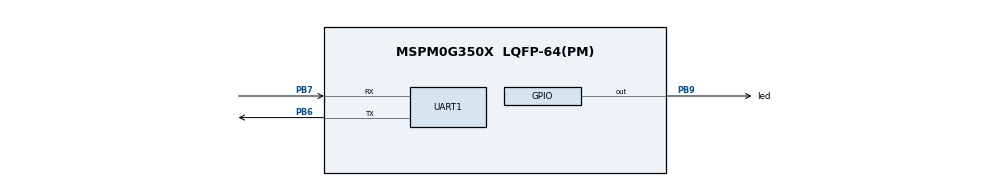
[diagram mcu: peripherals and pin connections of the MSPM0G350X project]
/**
 *
 * @cliArgs --device "MSPM0G350X" --part "Default" --package "LQFP-64(PM)" --product "mspm0_sdk@2.10.00.04"
 * @versions {"tool":"1.28.1+4785"}
 */

/**
 * Import the modules used in this configuration.
 */
const GPIO    = scripting.addModule("/ti/driverlib/GPIO", {}, false);
const GPIO1   = GPIO.addInstance();
const SYSCTL  = scripting.addModule("/ti/driverlib/SYSCTL");
const SYSTICK = scripting.addModule("/ti/driverlib/SYSTICK");
const TIMER   = scripting.addModule("/ti/driverlib/TIMER", {}, false);
const TIMER1  = TIMER.addInstance();
const UART    = scripting.addModule("/ti/driverlib/UART", {}, false);
const UART1   = UART.addInstance();

/**
 * Write custom configuration values to the imported modules.
 */
const divider7       = system.clockTree["PLL_PDIV"];
divider7.divideValue = 2;

const divider9       = system.clockTree["UDIV"];
divider9.divideValue = 2;

const gate7  = system.clockTree["MFCLKGATE"];
gate7.enable = true;

const multiplier2         = system.clockTree["PLL_QDIV"];
multiplier2.multiplyValue = 5;

const mux8       = system.clockTree["HSCLKMUX"];
mux8.inputSelect = "HSCLKMUX_SYSPLL2X";

GPIO1.$name                         = "LED";
GPIO1.associatedPins[0].$name       = "led";
GPIO1.associatedPins[0].pin.$assign = "PB9";

const Board = scripting.addModule("/ti/driverlib/Board", {}, false);

SYSCTL.forceDefaultClkConfig = true;
SYSCTL.clockTreeEn           = true;

SYSTICK.periodEnable  = true;
SYSTICK.systickEnable = true;
SYSTICK.period        = 16777216;

TIMER1.$name              = "TIMER_0";
TIMER1.timerClkPrescale   = 32;
TIMER1.timerMode          = "PERIODIC";
TIMER1.timerStartTimer    = true;
TIMER1.interrupts         = ["ZERO"];
TIMER1.interruptPriority  = "1";
TIMER1.timerPeriod        = "6.667 ms";
TIMER1.peripheral.$assign = "TIMG0";

UART1.$name                            = "UART_1";
UART1.targetBaudRate                   = 115200;
UART1.interruptPriority                = "3";
UART1.peripheral.$assign               = "UART1";
UART1.peripheral.rxPin.$assign         = "PB7";
UART1.peripheral.txPin.$assign         = "PB6";
UART1.txPinConfig.direction            = scripting.forceWrite("OUTPUT");
UART1.txPinConfig.hideOutputInversion  = scripting.forceWrite(false);
UART1.txPinConfig.onlyInternalResistor = scripting.forceWrite(false);
UART1.txPinConfig.passedPeripheralType = scripting.forceWrite("Digital");
UART1.txPinConfig.$name                = "ti_driverlib_gpio_GPIOPinGeneric6";
UART1.rxPinConfig.hideOutputInversion  = scripting.forceWrite(false);
UART1.rxPinConfig.onlyInternalResistor = scripting.forceWrite(false);
UART1.rxPinConfig.passedPeripheralType = scripting.forceWrite("Digital");
UART1.rxPinConfig.$name                = "ti_driverlib_gpio_GPIOPinGeneric7";

/**
 * Pinmux solution for unlocked pins/peripherals. This ensures that minor changes to the automatic solver in a future
 * version of the tool will not impact the pinmux you originally saw.  These lines can be completely deleted in order to
 * re-solve from scratch.
 */
Board.peripheral.$suggestSolution          = "DEBUGSS";
Board.peripheral.swclkPin.$suggestSolution = "PA20";
Board.peripheral.swdioPin.$suggestSolution = "PA19";
